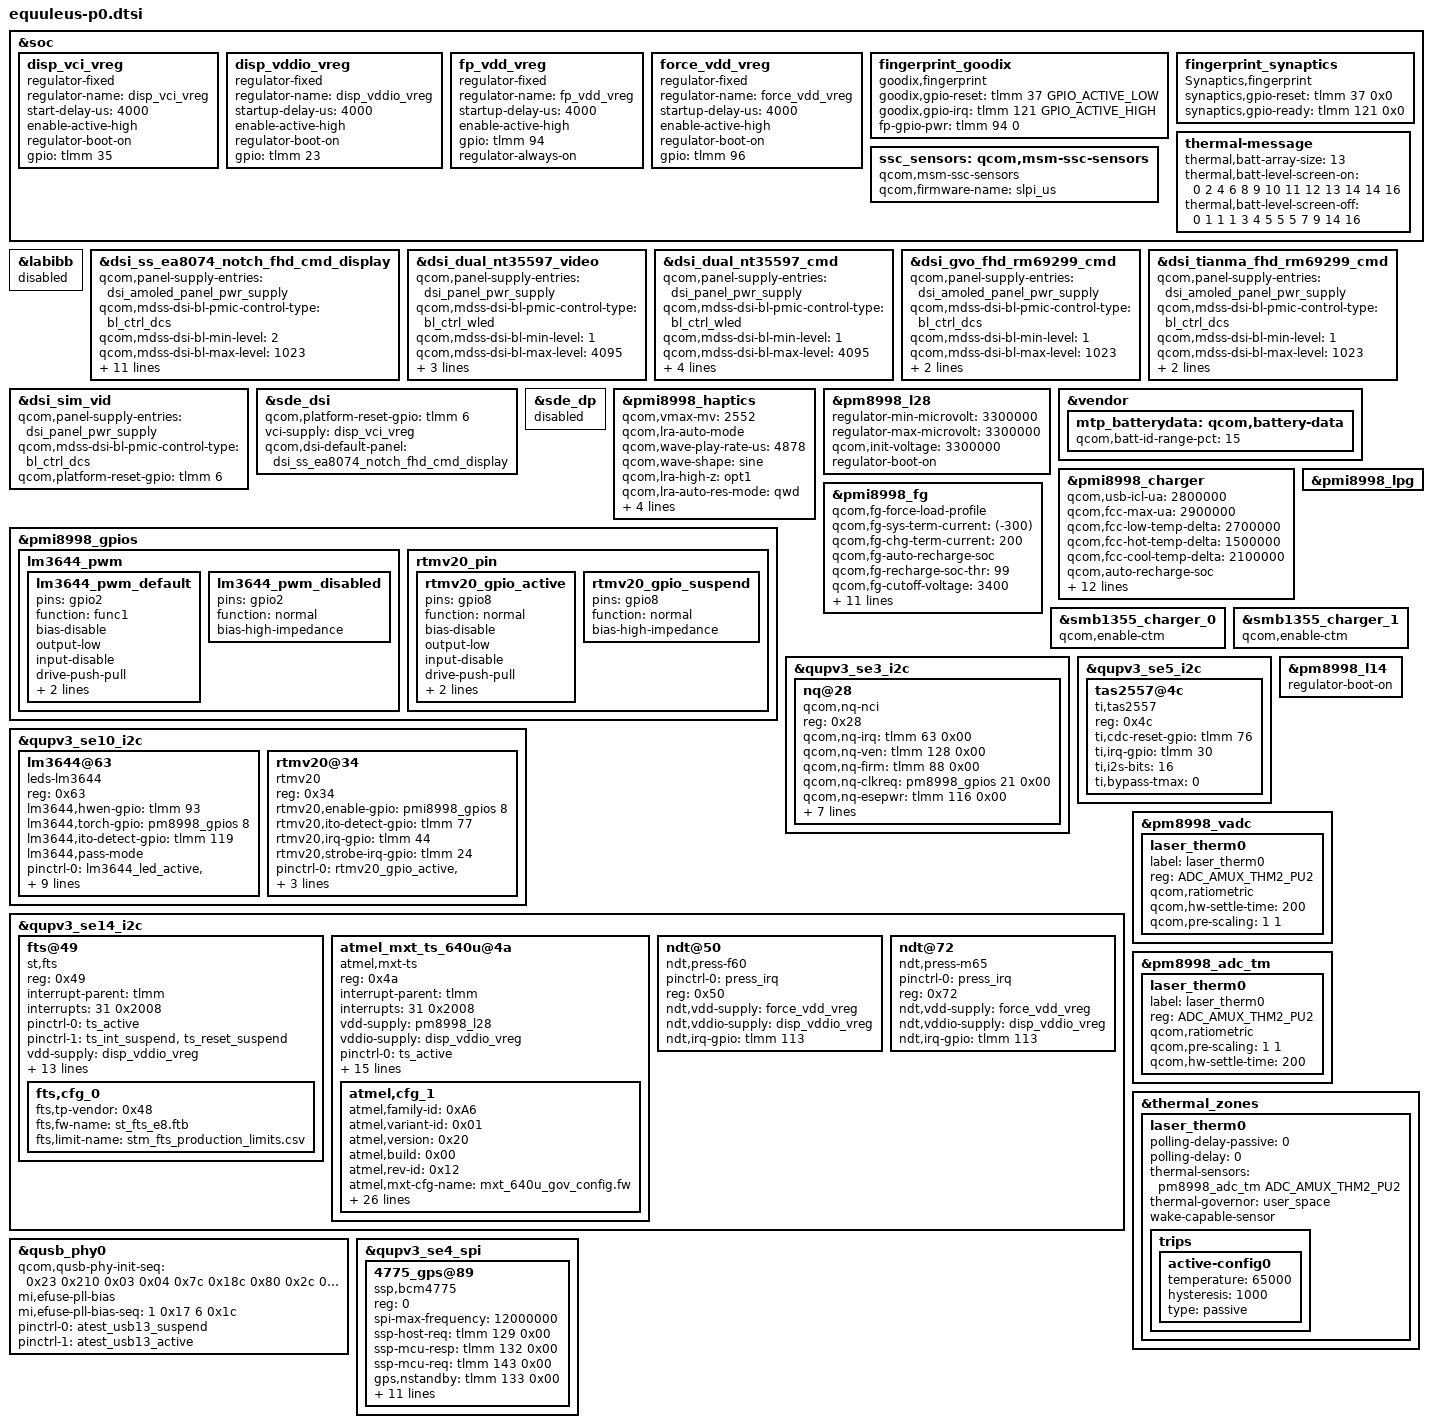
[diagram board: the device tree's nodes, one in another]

/* Copyright (c) 2016-2017, The Linux Foundation. All rights reserved.
 * Copyright (C) 2019 XiaoMi, Inc.
 *
 * This program is free software; you can redistribute it and/or modify
 * it under the terms of the GNU General Public License version 2 and
 * only version 2 as published by the Free Software Foundation.
 *
 * This program is distributed in the hope that it will be useful,
 * but WITHOUT ANY WARRANTY; without even the implied warranty of
 * MERCHANTABILITY or FITNESS FOR A PARTICULAR PURPOSE.  See the
 * GNU General Public License for more details.
 */
#include <dt-bindings/gpio/gpio.h>
#include "../../qcom/sdm845-pmic-overlay.dtsi"
#include "../../qcom/sdm845-pinctrl-overlay.dtsi"
//#include "dipper-camera-sensor-mtp.dtsi"
#include "equuleus-p0-camera-sensor-mtp.dtsi"

/* Xiaomi-common */
#include "../common/base_dts/sdm845.dtsi"
#include "../common/base_overlay/sdm845-pmic-overlay.dtsi"
#include "../common/xiaomi_common.dtsi"
#include "../common/xiaomi-common-sde-display.dtsi"

&soc {
	disp_vci_vreg: disp_vci_vreg {
		compatible = "regulator-fixed";
		regulator-name = "disp_vci_vreg";
		start-delay-us = <4000>;
		enable-active-high;
		regulator-boot-on;
		gpio = <&tlmm 35 0>;
	};

	disp_vddio_vreg: disp_vddio_vreg {
		compatible = "regulator-fixed";
		regulator-name = "disp_vddio_vreg";
		startup-delay-us = <4000>;
		enable-active-high;
		regulator-boot-on;
		gpio = <&tlmm 23 0>;
	 };

	fp_vdd_vreg: fp_vdd_vreg {
		compatible = "regulator-fixed";
		regulator-name = "fp_vdd_vreg";
		startup-delay-us = <4000>;
		enable-active-high;
		gpio = <&tlmm 94 0>;
		regulator-always-on;
	};

	force_vdd_vreg: force_vdd_vreg {
		compatible = "regulator-fixed";
		regulator-name = "force_vdd_vreg";
		startup-delay-us = <4000>;
		enable-active-high;
		regulator-boot-on;
		gpio = <&tlmm 96 0>;
	};

	fingerprint_goodix {
		compatible = "goodix,fingerprint";
		goodix,gpio-reset = <&tlmm 37 GPIO_ACTIVE_LOW>;
		goodix,gpio-irq = <&tlmm 121 GPIO_ACTIVE_HIGH>;
		fp-gpio-pwr = <&tlmm 94 0>;
		status = "ok";
	};

	fingerprint_synaptics {
		compatible = "Synaptics,fingerprint";
		synaptics,gpio-reset = <&tlmm 37 0x0>;
		synaptics,gpio-ready = <&tlmm 121 0x0>;
		status = "ok";
	};

	thermal-message {
		thermal,batt-array-size = "13";
		thermal,batt-level-screen-on = "0 2 4 6 8 9 10 11 12 13 14 14 16";
		thermal,batt-level-screen-off = "0 1 1 1 3 4 5 5 5 7 9 14 16";
	};
};

&labibb {
	status = "disabled";
};

&dsi_ss_ea8074_notch_fhd_cmd_display {
	qcom,panel-supply-entries = <&dsi_amoled_panel_pwr_supply>;
	qcom,mdss-dsi-bl-pmic-control-type = "bl_ctrl_dcs";
	qcom,mdss-dsi-bl-min-level = <2>;
	qcom,mdss-dsi-bl-max-level = <1023>;
	qcom,platform-reset-gpio = <&tlmm 6 0>;
	qcom,platform-te-gpio = <&tlmm 10 0>;
	qcom,esd-check-enabled;
	qcom,mdss-dsi-panel-status-check-mode = "reg_read";
	qcom,mdss-dsi-panel-status-command = [
		06 01 00 01 00 00 01 0A
		06 01 00 01 00 00 01 0D];
	qcom,mdss-dsi-panel-status-command-state = "dsi_hs_mode";
	qcom,mdss-dsi-panel-status-value = <0x9c 0x00>;
	qcom,mdss-dsi-panel-status-read-length = <1 1>;
};

&dsi_dual_nt35597_video {
	qcom,panel-supply-entries = <&dsi_panel_pwr_supply>;
	qcom,mdss-dsi-bl-pmic-control-type = "bl_ctrl_wled";
	qcom,mdss-dsi-bl-min-level = <1>;
	qcom,mdss-dsi-bl-max-level = <4095>;
	qcom,mdss-dsi-mode-sel-gpio-state = "dual_port";
	qcom,panel-mode-gpio = <&tlmm 52 0>;
	qcom,platform-reset-gpio = <&tlmm 6 0>;
};

&dsi_dual_nt35597_cmd {
	qcom,panel-supply-entries = <&dsi_panel_pwr_supply>;
	qcom,mdss-dsi-bl-pmic-control-type = "bl_ctrl_wled";
	qcom,mdss-dsi-bl-min-level = <1>;
	qcom,mdss-dsi-bl-max-level = <4095>;
	qcom,mdss-dsi-mode-sel-gpio-state = "dual_port";
	qcom,panel-mode-gpio = <&tlmm 52 0>;
	qcom,platform-reset-gpio = <&tlmm 6 0>;
	qcom,platform-te-gpio = <&tlmm 10 0>;
};

&dsi_gvo_fhd_rm69299_cmd {
	qcom,panel-supply-entries = <&dsi_amoled_panel_pwr_supply>;
	qcom,mdss-dsi-bl-pmic-control-type = "bl_ctrl_dcs";
	qcom,mdss-dsi-bl-min-level = <1>;
	qcom,mdss-dsi-bl-max-level = <1023>;
	qcom,platform-reset-gpio = <&tlmm 6 0>;
	qcom,platform-te-gpio = <&tlmm 10 0>;
};

&dsi_tianma_fhd_rm69299_cmd {
	qcom,panel-supply-entries = <&dsi_amoled_panel_pwr_supply>;
	qcom,mdss-dsi-bl-pmic-control-type = "bl_ctrl_dcs";
	qcom,mdss-dsi-bl-min-level = <1>;
	qcom,mdss-dsi-bl-max-level = <1023>;
	qcom,platform-reset-gpio = <&tlmm 6 0>;
	qcom,platform-te-gpio = <&tlmm 10 0>;
};

&dsi_sim_vid {
	qcom,panel-supply-entries = <&dsi_panel_pwr_supply>;
	qcom,mdss-dsi-bl-pmic-control-type = "bl_ctrl_dcs";
	qcom,platform-reset-gpio = <&tlmm 6 0>;
};

&sde_dsi {
	qcom,platform-reset-gpio = <&tlmm 6 0>;
	vci-supply = <&disp_vci_vreg>;
	qcom,dsi-default-panel = <&dsi_ss_ea8074_notch_fhd_cmd_display>;
};

&sde_dp {
	status = "disabled";
};

&pmi8998_haptics {
	qcom,vmax-mv = <2552>;
	qcom,lra-auto-mode;
	qcom,wave-play-rate-us = <4878>;
	qcom,wave-shape = "sine";
	qcom,lra-high-z = "opt1";
	qcom,lra-auto-res-mode = "qwd";
	qcom,lra-res-cal-period = <4>;
	qcom,effect-max = <3>;
	qcom,effect-arry = [3e 3e be 00 00 00 00 00
		3e 3e 3e be be 00 00 00
		3e 3e 3e 3e be be 00 00];
	status = "okay";
};

&pm8998_l28{
	regulator-min-microvolt = <3300000>;
	regulator-max-microvolt = <3300000>;
	qcom,init-voltage = <3300000>;
	regulator-boot-on;
};

&vendor {
	mtp_batterydata: qcom,battery-data {
		qcom,batt-id-range-pct = <15>;
		#include "battery/batterydata-e8-coslight-3000mAh.dtsi"
		#include "battery/batterydata-e8-atl-3000mAh.dtsi"
	};
};

&pmi8998_gpios {
	lm3644_pwm {
		lm3644_pwm_default: lm3644_pwm_default {
			    pins = "gpio2";
			    function = "func1";
			    bias-disable;
			    output-low;
			    input-disable;
			    drive-push-pull;
			    qcom,drive-strength = <2>;
			    power-source = <0>;
		};

		lm3644_pwm_disabled: lm3644_pwm_disabled {
			    pins = "gpio2";
			    function = "normal";
			    bias-high-impedance;
		};
	};

	rtmv20_pin {
		rtmv20_gpio_active: rtmv20_gpio_active {
			pins = "gpio8";
			function = "normal";
			bias-disable;
			output-low;
			input-disable;
			drive-push-pull;
			qcom,drive-strength = <2>;
			power-source = <1>;
		};

		rtmv20_gpio_suspend: rtmv20_gpio_suspend {
			pins = "gpio8";
			function = "normal";
			bias-high-impedance;
		};
	};
};

&pmi8998_charger {
	qcom,usb-icl-ua = <2800000>;
	qcom,fcc-max-ua = <2900000>;
	qcom,fcc-low-temp-delta = <2700000>;
	qcom,fcc-hot-temp-delta = <1500000>;
	qcom,fcc-cool-temp-delta = <2100000>;
	qcom,auto-recharge-soc;
	qcom,sw-jeita-enable;
	qcom,dynamic-fv-enable;
	qcom,thermal-mitigation
				= <1800000 1600000 1400000 1200000 1000000 1000000 1000000>;
	qcom,thermal-mitigation-dcp
				= <1800000 1800000 1800000 1800000 1800000 1800000 1800000
				   1800000 1800000 1800000 1800000 1800000 1600000 1400000
				   1200000 1000000>;
	qcom,thermal-mitigation-qc3
				= <2800000 2725000 2575000 2425000 2275000 2125000 2000000
				   1800000 1650000 1500000 1360000 1200000 1060000 900000
				   750000 525000>;
	qcom,thermal-mitigation-qc2
				= <1625000 1625000 1625000 1625000 1625000 1525000 1425000
				   1325000 1225000 1125000 1025000 925000 825000 750000
				   625000 525000>;
	qcom,thermal-mitigation-pd-base
				= <3000000 2800000 2600000 2400000 2200000 2000000 1800000
				   1600000 1600000 1400000 1200000 1100000 1000000 900000
				   750000 525000>;
};

&pmi8998_fg {
	qcom,fg-force-load-profile;
	qcom,fg-sys-term-current = <(-300)>;
	qcom,fg-chg-term-current = <200>;
	qcom,fg-auto-recharge-soc;
	qcom,fg-recharge-soc-thr = <99>;
	qcom,fg-cutoff-voltage = <3400>;
	qcom,fg-cutoff-current = <200>;
	qcom,fg-empty-voltage = <3100>;
	qcom,fg-jeita-hyst-temp = <2>;
	qcom,fg-jeita-thresholds = <0 15 45 60>;
	qcom,fg-esr-clamp-mohms = <60>;
	qcom,fg-batt-temp-delta = <6>;
	qcom,optimize-sram-seq = <
		0x9 0x3 0x2
		0xA 0x0 0x1
		0xA 0x1 0x0
		0xA 0x2 0x6
		0xA 0x3 0x20
		0xC 0x1 0x12>;
	qcom,battery-data = <&mtp_batterydata>;
	qcom,slope-limit-temp-threshold = <100>;
	qcom,slope-limit-coeffs = <10 11 12 13>;
};

&pmi8998_lpg {
	status = "okay";
};

&smb1355_charger_0 {
	status = "ok";
	qcom,enable-ctm;
};

&smb1355_charger_1 {
	status = "ok";
	qcom,enable-ctm;
};

&qupv3_se3_i2c {
	status = "ok";
	nq@28 {
		compatible = "qcom,nq-nci";
		reg = <0x28>;
		qcom,nq-irq = <&tlmm 63 0x00>;
		qcom,nq-ven = <&tlmm 128 0x00>;
		qcom,nq-firm = <&tlmm 88 0x00>;
		qcom,nq-clkreq = <&pm8998_gpios 21 0x00>;
		qcom,nq-esepwr = <&tlmm 116 0x00>;
		interrupt-parent = <&tlmm>;
		qcom,clk-src = "BBCLK3";
		interrupts = <63 0>;
		interrupt-names = "nfc_irq";
		pinctrl-names = "nfc_active", "nfc_suspend";
		pinctrl-0 = <&nfc_int_active
				&nfc_enable_active
				&nfc_clk_default>;
		pinctrl-1 = <&nfc_int_suspend &nfc_enable_suspend>;
		clocks = <&clock_rpmh RPMH_LN_BB_CLK3>;
		clock-names = "ref_clk";
	};
};

&qupv3_se5_i2c {
	status = "ok";
	tas2557@4c {
		compatible = "ti,tas2557";
		reg = <0x4c>;
		ti,cdc-reset-gpio = <&tlmm 76 0>;
		ti,irq-gpio = <&tlmm 30 0>;
		ti,i2s-bits = <16>;   /* support 16, 24, 32 */
		ti,bypass-tmax = <0>;   /* 0, not bypass; 1, bypass */
	};

};
&qupv3_se10_i2c {
	status = "ok";

	lm3644@63 {
		compatible = "leds-lm3644";
		reg = <0x63>;
		lm3644,hwen-gpio = <&tlmm 93 0x00>;
		lm3644,torch-gpio = <&pm8998_gpios 8 0x00>;
		lm3644,ito-detect-gpio = <&tlmm 119 0x00>;
		lm3644,pass-mode;
		pinctrl-names = "lm3644_led_active", "lm3644_led_active_pwm", "lm3644_led_suspend";
		pinctrl-0 = <&lm3644_led_active &lm3644_pwm_disabled>;
		pinctrl-1 = <&lm3644_led_active &lm3644_pwm_default>;
		pinctrl-2 = <&lm3644_led_suspend &lm3644_pwm_disabled>;

		lm3644,use-simulative-pwm;
		pwms = <&pmi8998_lpg 1 25000>;
		lm3644,period-us = <25000>;
		lm3644,duty-us = <2500>;
	};

	rtmv20@34 {
		compatible = "rtmv20";
		reg = <0x34>;
		rtmv20,enable-gpio = <&pmi8998_gpios 8 GPIO_ACTIVE_HIGH>;
		rtmv20,ito-detect-gpio = <&tlmm 77 0x00>;
		rtmv20,irq-gpio = <&tlmm 44 0x00>;
		rtmv20,strobe-irq-gpio = <&tlmm 24 0x00>;
		pinctrl-names = "rtmv20_gpio_active", "rtmv20_gpio_suspend";
		pinctrl-0 = <&rtmv20_gpio_active &rtmv20_exception_active>;
		pinctrl-1 = <&rtmv20_gpio_suspend &rtmv20_exception_suspend>;
	};
};

&qupv3_se14_i2c {
	status = "ok";
	fts@49 {
		compatible = "st,fts";
		reg = <0x49>;
		interrupt-parent = <&tlmm>;
		interrupts = <31 0x2008>;
		pinctrl-names = "pmx_ts_active", "pmx_ts_suspend";
		pinctrl-0 = <&ts_active>;
		pinctrl-1 = <&ts_int_suspend &ts_reset_suspend>;
		vdd-supply = <&disp_vddio_vreg>;
		avdd-supply = <&pm8998_l28>;
		fts,pwr-reg-name = "avdd";
		fts,bus-reg-name = "vdd";
		fts,irq-gpio = <&tlmm 31 0x2008>;
		fts,irq-gpio-name = "fts_irq";
		fts,reset-gpio-enable;
		fts,reset-gpio = <&tlmm 32 0x00>;
		fts,reset-gpio-name = "fts_rst";
		fts,irq-flags = <0x2008>; /* IRQF_ONESHOT | IRQF_TRIGGER_LOW */
		fts,key-num = <2>;
		fts,key-codes = <158 139>;
//		fts,side-volume;
//		fts,x-base = <1439>;
//		fts,y-base = <50>;
//		fts,y-offset = <300>;
//		fts,y-skip = <240>;
		fts,config-array-size = <1>;
		fts,default-fw-name = "st_fts_e8.ftb";
		fts,cfg_0 {
			fts,tp-vendor = <0x48>;
			fts,fw-name = "st_fts_e8.ftb";
			fts,limit-name = "stm_fts_production_limits.csv";
		};
	};
	atmel_mxt_ts_640u@4a {
		compatible = "atmel,mxt-ts";
		reg = <0x4a>;
		interrupt-parent = <&tlmm>;
		interrupts = <31 0x2008>;
		vdd-supply = <&pm8998_l28>;
		vddio-supply = <&disp_vddio_vreg>;
		/* pins used by touchscreen */
		pinctrl-names = "pmx_ts_active","pmx_ts_suspend";
		pinctrl-0 = <&ts_active>;
		pinctrl-1 = <&ts_int_suspend &ts_reset_suspend>;
		atmel,reset-gpio = <&tlmm 32 0x00>;
		atmel,reset-low-prepower;
		atmel,irq-gpio = <&tlmm 31 0x2008>;
		atmel,mxt-fw-name = "mXT640U2000.fw";
		atmel,config-array-size = <1>;
		atmel,default-config = <0>;
		atmel,default-panel-id = <0x51>;
		atmel,irqflags = <0x2008>;
		atmel,gpio-mask = <0xC>;
		atmel,esd-reset;
		atmel,no-keys;
		atmel,use-ta-gpio;
		atmel,raw-min = <3000>;
		atmel,raw-max = <7000>;
		atmel,cfg_1 {
			atmel,family-id = <0xA6>;
			atmel,variant-id = <0x01>;
			atmel,version = <0x20>;
			atmel,build = <0x00>;
			atmel,rev-id = <0x12>;
			atmel,mxt-cfg-name = "mxt_640u_gov_config.fw";
			atmel,vendor-id = <0x0C>;
			atmel,panel-id = <0x51>; /* gov id = 0x51 */
			atmel,key-codes = <158 139 102>;
			atmel,selfintthr-stylus = <0>;
			atmel,t71-tchthr-pos = <22>;
			atmel,self-chgtime-min = <0>;
			atmel,self-chgtime-max = <0>;
			atmel,mult-intthr-sensitive = <0x08>;
			atmel,mult-intthr-not-sensitive = <17>;
			atmel,atchthr-sensitive = <6>;
			atmel,mult-tchthr-sensitive = <0x14>;
			atmel,mult-tchthr-not-sensitive = <0>;
			atmel,wake-up-self-adcx = <16>;
			atmel,atchratio = <0>;
			atmel,xycfg = <0x08>;
			atmel,xsize = <0x1e>;
			atmel,xrange-lsb = <0x37>;
			atmel,xrange-msb = <0x04>;
			atmel,tchhyst = <0x0a>;
			atmel,intthrhyst = <0x03>;
			atmel,xtchthr = <0x23>;
			atmel,xtchhyst = <0x0f>;
			atmel,intthrx = <0x08>;
			atmel,ytchthr = <0x23>;
			atmel,ytchhyst = <0x0f>;
			atmel,intthry = <0x08>;
		};
	};

	ndt@50 {
		compatible = "ndt,press-f60";
		pinctrl-names = "default";
		pinctrl-0 = <&press_irq>;
		reg = <0x50>;
		ndt,vdd-supply = <&force_vdd_vreg>;
		ndt,vddio-supply = <&disp_vddio_vreg>;
		ndt,irq-gpio = <&tlmm 113 0>;
	};

	ndt@72 {
		compatible = "ndt,press-m65";
		pinctrl-names = "default";
		pinctrl-0 = <&press_irq>;
		reg = <0x72>;
		ndt,vdd-supply = <&force_vdd_vreg>;
		ndt,vddio-supply = <&disp_vddio_vreg>;
		ndt,irq-gpio = <&tlmm 113 0>;
	};
};

&pm8998_l14 {
	regulator-boot-on;
};

&pm8998_vadc {
	/delete-node/ cam_therm1;

	laser_therm0 {
		label = "laser_therm0";
		reg = <ADC_AMUX_THM2_PU2>;
		qcom,ratiometric;
		qcom,hw-settle-time = <200>;
		qcom,pre-scaling = <1 1>;
	};
};

&pm8998_adc_tm {
	/delete-node/ cam_therm1;

	laser_therm0 {
		label = "laser_therm0";
		reg = <ADC_AMUX_THM2_PU2>;
		qcom,ratiometric;
		qcom,pre-scaling = <1 1>;
		qcom,hw-settle-time = <200>;
	};
};

&thermal_zones {
	/delete-node/ cam_therm1;

	laser_therm0 {
		polling-delay-passive = <0>;
		polling-delay = <0>;
		thermal-sensors = <&pm8998_adc_tm ADC_AMUX_THM2_PU2>;
		thermal-governor = "user_space";
		wake-capable-sensor;

		trips {
			active-config0 {
					temperature = <65000>;
					hysteresis = <1000>;
					type = "passive";
			};
		};
	};
};

&qusb_phy0 {
		qcom,qusb-phy-init-seq =
			/* <value reg_offset> */
			   <0x23 0x210 /* PWR_CTRL1 */
			    0x03 0x04  /* PLL_ANALOG_CONTROLS_TWO */
			    0x7c 0x18c /* PLL_CLOCK_INVERTERS */
			    0x80 0x2c  /* PLL_CMODE */
			    0x0a 0x184 /* PLL_LOCK_DELAY */
			    0x19 0xb4  /* PLL_DIGITAL_TIMERS_TWO */
			    0x40 0x194 /* PLL_BIAS_CONTROL_1 */
			    0x20 0x198 /* PLL_BIAS_CONTROL_2 */
			    0x21 0x214 /* PWR_CTRL2 */
			    0x08 0x220 /* IMP_CTRL1 */
			    0x58 0x224 /* IMP_CTRL2 */
			    0x07 0x240 /* TUNE1 */
			    0x29 0x244 /* TUNE2 */
			    0xca 0x248 /* TUNE3 */
			    0x04 0x24c /* TUNE4 */
			    0x03 0x250 /* TUNE5 */
			    0x00 0x23c /* CHG_CTRL2 */
			    0x22 0x210>; /* PWR_CTRL1 */
			    mi,efuse-pll-bias;
			    mi,efuse-pll-bias-seq = <1 0x17 6 0x1c>;
	pinctrl-names = "atest_usb13_suspend","atest_usb13_active";
	pinctrl-0 = <&atest_usb13_suspend>;
	pinctrl-1 = <&atest_usb13_active>;
};

&soc {
	disp_vddio_vreg {
		/delete-property/ gpio;
		gpio = <&tlmm 23 0>;
	};
};

&qupv3_se4_spi {
	status = "ok";
	4775_gps@89 {
			compatible = "ssp,bcm4775";
			reg = <0>;
			spi-max-frequency = <12000000>;
			ssp-host-req = <&tlmm 129 0x00>;
			ssp-mcu-resp = <&tlmm 132 0x00>;
			ssp-mcu-req = <&tlmm 143 0x00>;
			gps,nstandby = <&tlmm 133 0x00>;
			interrupt-parent = <&tlmm>;
			interrupts = <129 0>;
			spi-cpha;
			spi-cpol;
			interrupt-names = "gps_irq";
			gps,power_enable = <&pm8998_gpios 19 GPIO_ACTIVE_HIGH>;
			pinctrl-names = "gps_active", "gps_suspend";
			pinctrl-0 = <&gps_int_active
			&gps_enable_active
			&gps_clk_default
			&gps_power_default
			&gps_resp_active>;
			pinctrl-1 = <&gps_int_suspend &gps_enable_suspend &gps_resp_suspend>;
		};
};

&soc {
	ssc_sensors: qcom,msm-ssc-sensors {
		compatible = "qcom,msm-ssc-sensors";
		status = "ok";
		qcom,firmware-name = "slpi_us";
	};
};
